# M451_v1 register map
File version: 1.0
Registers are 32-bit, read-write, reset 0x0 unless marked. A register's access mark holds for its fields unless they carry their own. Offsets are from the block's base; [hi:lo] are bit positions; {n}, {i} and the like mark numbered series.

## DSCT_DA — PDMA Register Map
Base 0x40008008
{0x0+0x10*i} PDMA_DSCT{i}_DA reset not defined (i=0..11) — Destination Address Register of PDMA Channel n (M45xD/M45xC Only Support Channel 0~7)
  [31:0] DA — PDMA Transfer Destination Address Register. This field indicates a 32-bit destination address of PDMA controller.

## DSCT_NEXT — PDMA Register Map
Base 0x4000800C
{0x0+0x10*i} PDMA_DSCT{i}_NEXT reset not defined (i=0..11) — First Scatter-gather Descriptor Table Offset Address of PDMA Channel n (M45xD/M45xC Only Support Channel 0~7)
  [15:2] NEXT — PDMA Next Descriptor Table Offset Address Register. This field indicates the offset of next descriptor table address in system memory. The system memory based address is 0x2000_0000 (PDMA_SCATBA), if the next descriptor table is 0x2000_0100, then this field must fill in 0x0100. Note1: The next descriptor table address must be word boundary. Note2: Before filled transfer task in the descriptor table, user must check if the descriptor table is complete.

## DSCT_SA — PDMA Register Map
Base 0x40008004
{0x0+0x10*i} PDMA_DSCT{i}_SA reset not defined (i=0..11) — Source Address Register of PDMA Channel n (M45xD/M45xC Only Support Channel 0~7)
  [31:0] SA — PDMA Transfer Source Address Register. This field indicates a 32-bit source address of PDMA controller.

## WWDT — WWDT Register Map
Base 0x40040100
0x00 WWDT_RLDCNT wo — WWDT Reload Counter Register
  [31:0] RLDCNT — WWDT Reload Counter Register. Writing 0x00005AA5 to this register will reload the WWDT counter value to 0x3F. Note: User can only write WWDT_RLDCNT register to reload WWDT counter value when current WWDT counter value between 0 and CMPDAT (WWDT_CTL[21:16]). If user writes WWDT_RLDCNT when current WWDT counter value is larger than CMPDAT , WWDT reset signal will generate immediately.
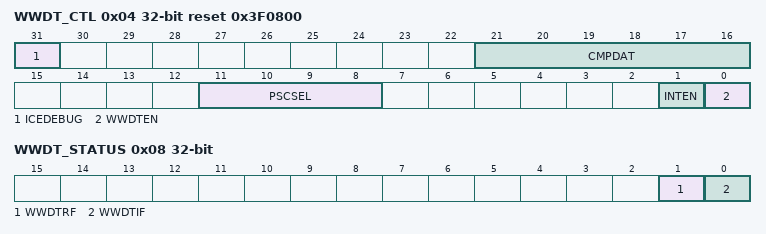
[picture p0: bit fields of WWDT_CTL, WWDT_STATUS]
0x04 WWDT_CTL reset 0x3F0800 — WWDT Control Register
  [31] ICEDEBUG — ICE Debug Mode Acknowledge Disable Control. WWDT down counter will keep going no matter CPU is held by ICE or not.
    0=ICE debug mode acknowledgement effects WWDT counting; 1=ICE debug mode acknowledgement Disabled
  [21:16] CMPDAT — WWDT Window Compare Register. Set this register to adjust the valid reload window. Note: User can only write WWDT_RLDCNT register to reload WWDT counter value when current WWDT counter value between 0 and CMPDAT. If user writes WWDT_RLDCNT register when current WWDT counter value larger than CMPDAT, WWDT reset signal will generate immediately.
  [11:8] PSCSEL — WWDT Counter Prescale Period Selection
    0=Pre-scale is 1; Max time-out period is 1 * 64 * WWDT_CLK; 1=Pre-scale is 2; Max time-out period is 2 * 64 * WWDT_CLK; 2=Pre-scale is 4; Max time-out period is 4 * 64 * WWDT_CLK; 3=Pre-scale is 8; Max time-out period is 8 * 64 * WWDT_CLK; 4=Pre-scale is 16; Max time-out period is 16 * 64 * WWDT_CLK; 5=Pre-scale is 32; Max time-out period is 32 * 64 * WWDT_CLK; 6=Pre-scale is 64; Max time-out period is 64 * 64 * WWDT_CLK; 7=Pre-scale is 128; Max time-out period is 128 * 64 * WWDT_CLK; 8=Pre-scale is 192; Max time-out period is 192 * 64 * WWDT_CLK; 9=Pre-scale is 256; Max time-out period is 256 * 64 * WWDT_CLK; 10=Pre-scale is 384; Max time-out period is 384 * 64 * WWDT_CLK; 11=Pre-scale is 512; Max time-out period is 512 * 64 * WWDT_CLK; 12=Pre-scale is 768; Max time-out period is 768 * 64 * WWDT_CLK; 13=Pre-scale is 1024; Max time-out period is 1024 * 64 * WWDT_CLK; 14=Pre-scale is 1536; Max time-out period is 1536 * 64 * WWDT_CLK; 15=Pre-scale is 2048; Max time-out period is 2048 * 64 * WWDT_CLK
  [1] INTEN — WWDT Interrupt Enable Control Bit. If this bit is enabled, the WWDT counter compare match interrupt signal is generated and inform to CPU.
    0=WWDT counter compare match interrupt Disabled; 1=WWDT counter compare match interrupt Enabled
  [0] WWDTEN — WWDT Enable Control Bit. Set this bit to enable WWDT counter counting.
    0=WWDT counter is stopped; 1=WWDT counter is starting counting
0x08 WWDT_STATUS
  [1] WWDTRF — WWDT Timer-out Reset Flag. This bit indicates the system has been reset by WWDT time-out reset or not. Note: This bit is cleared by writing 1 to it.
    0=WWDT time-out reset did not occur; 1=WWDT time-out reset occurred
  [0] WWDTIF — WWDT Compare Match Interrupt Flag. This bit indicates the interrupt flag status of WWDT while WWDT counter value matches CMPDAT (WWDT_CTL[21:16]). Note: This bit is cleared by writing 1 to it.
    0=No effect; 1=WWDT counter value matches CMPDAT
0x0C WWDT_CNT ro reset 0x3F — WWDT Counter Value Register
  [5:0] CNTDAT — WWDT Counter Value. CNTDAT will be updated continuously to monitor 6-bit WWDT down counter value.
